AUTOSAR XML (schema 4-2-2)
standard types defined: float64, uint8, sint8, Double, UInt8, SInt8
package /Components
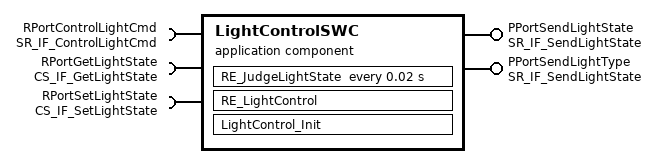
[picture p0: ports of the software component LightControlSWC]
  application sw component type LightControlSWC
    require port RPortControlLightCmd: nonqueued-receiver-com-spec{data-element=DEControlLightCmd, init-value=0}, required-interface=SR_IF_ControlLightCmd
    provide port PPortSendLightState: nonqueued-sender-com-spec{data-element=DESendLightState, init-value=0}, provided-interface=SR_IF_SendLightState
    provide port PPortSendLightType: nonqueued-sender-com-spec{data-element=DESendLightTyep, init-value=0}, provided-interface=SR_IF_SendLightState
    require port RPortGetLightState: required-interface=CS_IF_GetLightState
    require port RPortSetLightState: required-interface=CS_IF_SetLightState
    behavior untitled1_IB: handle-termination-and-restart=NO-SUPPORT
      timing event Event_JudgeLightState: start-on-event=RE_JudgeLightState, period=0.02
      init event Event_Init: start-on-event=LightControl_Init
      data received event Event_LightControl: start-on-event=RE_LightControl, data=RPortControlLightCmd.DEControlLightCmd
      implicit-inter-runnable-variables:
        data IRV_JudgeLightState: category=VALUE, sw-calibration-access=READ-ONLY, type=SInt8, init-value=0
      runnable RE_LightControl
        data-read-access:
          access IN_RPortControl_4e8c9f4821efe291: accessed-variable=RPortControlLightCmd.DEControlLightCmd
        data-write-access:
          access OUT_PPortSendLi_421bad6c683489b0: accessed-variable=PPortSendLightType.DESendLightTyep
          access OUT_PPortSendLi_ef01a88b79817ddc: accessed-variable=PPortSendLightState.DESendLightState
        read-local-variables:
          access RV_IRV_JudgeLightState: accessed-variable=IRV_JudgeLightState
        sync call SC_RPortSetLigh_73ca9ddede958029: operation=RPortSetLightState.OPSetLightState, timeout=1.0E-06
      runnable LightControl_Init
        data-write-access:
          access OUT_PPortSendLi_ef01a88b79817ddc: accessed-variable=PPortSendLightState.DESendLightState
      runnable RE_JudgeLightState
        sync call SC_RPortGetLigh_aa85752e71e49189: operation=RPortGetLightState.OPGetLightState, timeout=1.0E-06
        written-local-variables:
          access WV_IRV_JudgeLightState: accessed-variable=IRV_JudgeLightState
package /Components/SwcImplementations
  swc implementation untitled1_Impl: programming-language=C, sw-version=1.9.1, used-code-generator=Embedded Coder 7.9 (R2022b) 13-May-2022, vendor-id=0, behavior=untitled1_IB
    code-descriptors:
      code Code
        artifact-descriptors:
          short-label=LightControlSWC_c, category=SWSRC
          short-label=LightControlSWC_data_c, category=SWSRC
          short-label=LightControlSWC_h, category=SWHDR
          short-label=LightControlSWC_private_h, category=SWHDR
          short-label=LightControlSWC_types_h, category=SWHDR
          short-label=rtwtypes_h, category=SWHDR
    resource consumption RsrcCons_LightControlSWC
package /LightControlSWC_pkg/LightControlSWC_if
  sender receiver interface SR_IF_ControlLightCmd
    data DEControlLightCmd: category=VALUE, sw-calibration-access=READ-ONLY, type=Double
  sender receiver interface SR_IF_SendLightState
    data DESendLightState: category=VALUE, sw-calibration-access=READ-ONLY, type=Double
    data DESendLightTyep: category=VALUE, sw-calibration-access=READ-ONLY, type=Double
  client server interface CS_IF_GetLightState
    operation OPGetLightState
      arg DEGetLightState: category=VALUE, sw-calibration-access=READ-ONLY, type=UInt8, direction=OUT
  client server interface CS_IF_SetLightState
    operation OPSetLightState
      arg DESetLightState: category=VALUE, sw-calibration-access=READ-ONLY, type=SInt8, direction=IN
package /Timing
  swc timing LightControlSWC_timing: behavior=untitled1_IB
    timing-requirements:
      execution order constraint EOC
        ordered-elements:
          eoc executable entity ref RE_LightControl: executable=RE_LightControl, successor=RE_JudgeLightState
          eoc executable entity ref RE_JudgeLightState: executable=RE_JudgeLightState
